# fftc register map
Vendor: Texas Instruments
Peripheral module from a debugger description file (folder Keystone2).
Registers are 32-bit, read-write, no defined reset value unless marked. A register's access mark holds for its fields unless they carry their own. Offsets are as the file gives them; lines under a group give offsets from that group; [hi:lo] are bit positions; {n}, {i} and the like mark numbered series; 'fields as' and 'values as' point back to an identical list; <NAME> marks a mode.

## FFTC_5
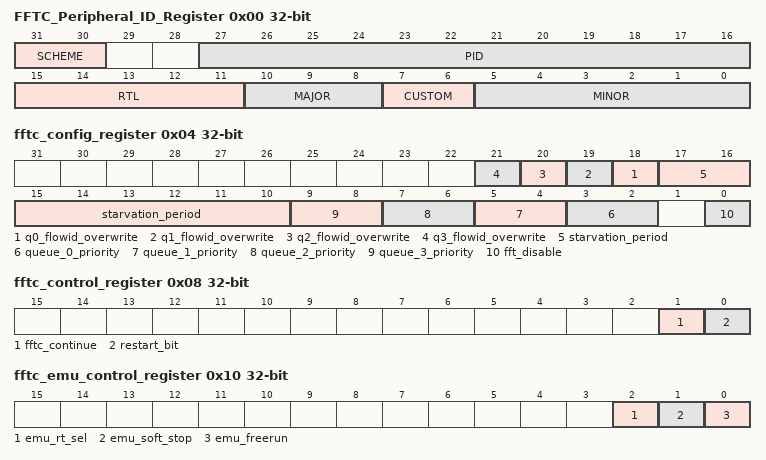
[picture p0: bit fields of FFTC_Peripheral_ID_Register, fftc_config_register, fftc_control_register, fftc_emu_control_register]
0x00 FFTC_Peripheral_ID_Register ro
  [31:30] SCHEME — PID Scheme
  [27:16] PID — Peripheral ID
  [15:11] RTL — RTL Rev Num
  [10:8] MAJOR — Major Rev Num
  [7:6] CUSTOM — Custom Rev Num
  [5:0] MINOR — Minor Rev Num
0x04 fftc_config_register
  [n+18] q{n}_flowid_overwrite (n=0..3) — Queue {n} flow_id overwrtie
  [17:10] starvation_period
  [2n+3:2n+2] queue_{n}_priority (n=0..3)
  [0] fft_disable — Discalbe FFT calculation
0x08 fftc_control_register wo
  [1] fftc_continue — FFTC resume work
  [0] restart_bit — FFTC SW restart
0x0C fftc_status_register ro
  [0] fftc_halted — FFTC has halted
0x10 fftc_emu_control_register
  [2] emu_rt_sel — FFTC emulation real time select
  [1] emu_soft_stop — FFTC emulation soft stop
  [0] emu_freerun — FFTC emulation free run
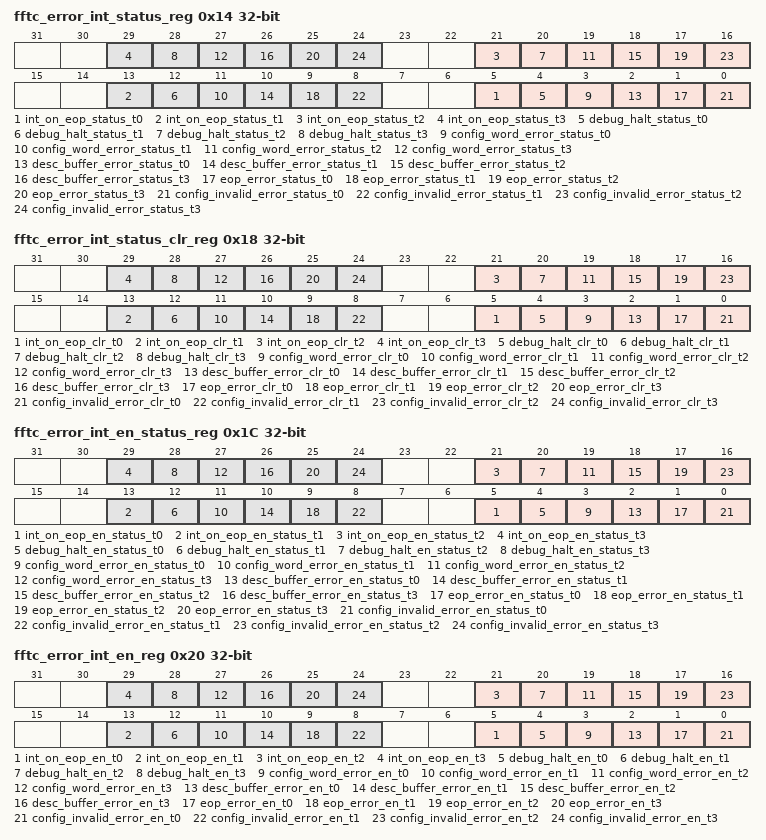
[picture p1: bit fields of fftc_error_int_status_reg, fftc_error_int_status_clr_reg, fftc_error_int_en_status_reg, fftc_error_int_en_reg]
0x14 fftc_error_int_status_reg
  [8n+5] int_on_eop_status_t{n} (n=0..3) — CPPI int on eop status and set
  [8n+4] debug_halt_status_t{n} (n=0..3) — debug halt interrupt status and set
  [8n+3] config_word_error_status_t{n} (n=0..3) — config word length error status and set
  [8n+2] desc_buffer_error_status_t{n} (n=0..3) — free descriptor buffer error status and set
  [8n+1] eop_error_status_t{n} (n=0..3) — eop error status and set
  [8n] config_invalid_error_status_t{n} (n=0..3) — config invalid error status and set
0x18 fftc_error_int_status_clr_reg wo
  [8n+5] int_on_eop_clr_t{n} (n=0..3) — CPPI int on eop status clear
  [8n+4] debug_halt_clr_t{n} (n=0..3) — debug halt interrupt status clear
  [8n+3] config_word_error_clr_t{n} (n=0..3) — config word length error statgus clear
  [8n+2] desc_buffer_error_clr_t{n} (n=0..3) — free descriptor buffer error status clear
  [8n+1] eop_error_clr_t{n} (n=0..3) — eop error status clear
  [8n] config_invalid_error_clr_t{n} (n=0..3) — config invalid error status clear
0x1C fftc_error_int_en_status_reg ro
  [8n+5] int_on_eop_en_status_t{n} (n=0..3) — CPPI int on eop status enabled
  [8n+4] debug_halt_en_status_t{n} (n=0..3) — debug halt interrupt status enabled
  [8n+3] config_word_error_en_status_t{n} (n=0..3) — config word length error statgus enabled
  [8n+2] desc_buffer_error_en_status_t{n} (n=0..3) — free descriptor buffer error status enabled
  [8n+1] eop_error_en_status_t{n} (n=0..3) — eop error status enabled
  [8n] config_invalid_error_en_status_t{n} (n=0..3) — config invalid error status enabled
0x20 fftc_error_int_en_reg
  [8n+5] int_on_eop_en_t{n} (n=0..3) — CPPI int on eop interrupt enable
  [8n+4] debug_halt_en_t{n} (n=0..3) — debug halt interrupt enable
  [8n+3] config_word_error_en_t{n} (n=0..3) — config word length error enable
  [8n+2] desc_buffer_error_en_t{n} (n=0..3) — free descriptor buffer error enable
  [8n+1] eop_error_en_t{n} (n=0..3) — eop error enable
  [8n] config_invalid_error_en_t{n} (n=0..3) — config invalid error enable
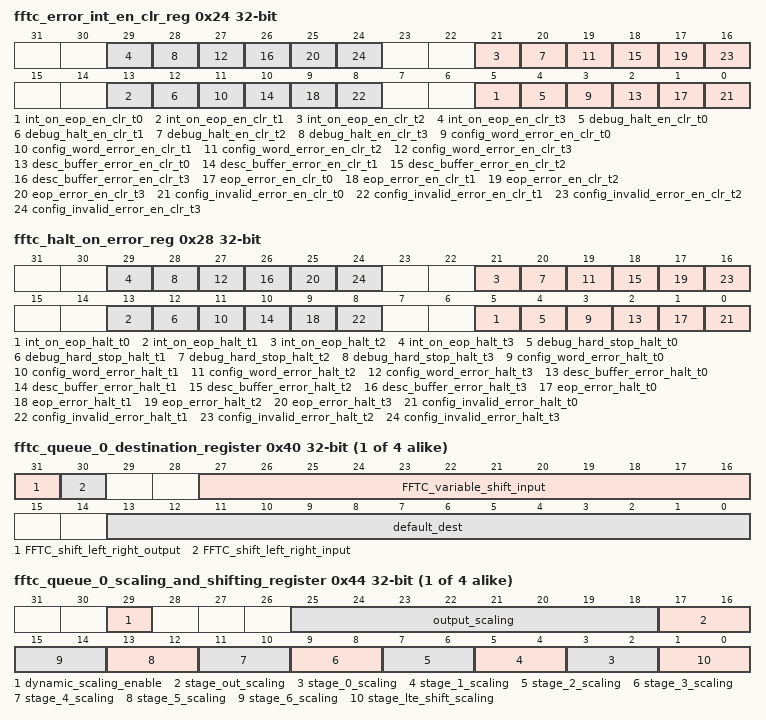
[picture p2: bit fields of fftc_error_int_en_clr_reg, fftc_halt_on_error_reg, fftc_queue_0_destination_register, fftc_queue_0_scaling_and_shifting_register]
0x24 fftc_error_int_en_clr_reg wo
  [8n+5] int_on_eop_en_clr_t{n} (n=0..3) — CPPI int on eop interrupt enable clear
  [8n+4] debug_halt_en_clr_t{n} (n=0..3) — debug halt interrupt enable clear
  [8n+3] config_word_error_en_clr_t{n} (n=0..3) — config word length error enable clear
  [8n+2] desc_buffer_error_en_clr_t{n} (n=0..3) — free descriptor buffer error enable clear
  [8n+1] eop_error_en_clr_t{n} (n=0..3) — eop error enable clear
  [8n] config_invalid_error_en_clr_t{n} (n=0..3) — config invalid error enable clear
0x28 fftc_halt_on_error_reg access per field
  [8n+5] int_on_eop_halt_t{n} rw (n=0..3) — CPPI int on eop interrupt halt on error
  [8n+4] debug_hard_stop_halt_t{n} ro (n=0..3) — CPPI hard stop halt on error status
  [8n+3] config_word_error_halt_t{n} rw (n=0..3) — config word length error halt
  [8n+2] desc_buffer_error_halt_t{n} rw (n=0..3) — free descriptor buffer error halt
  [8n+1] eop_error_halt_t{n} rw (n=0..3) — eop error halt
  [8n] config_invalid_error_halt_t{n} rw (n=0..3) — config invalid error halt
0x2C fftc_error_end_of_int_reg
  [7:0] eoi_val — EOI value
0x30 fftc_clipping_detect_register — (1 of 4, stride 4)
  [31:0] clipping_count — queue clipping count
{0x40+0x30*i} fftc_queue_{i}_destination_register (i=0..3)
  [31] FFTC_shift_left_right_output — set to 1 to enable
  [30] FFTC_shift_left_right_input — set to 1 to enable
  [27:16] FFTC_variable_shift_input — rotates the input sequence 2xFFTC_variable_shift_input samples to the right
  [13:0] default_dest — The CPPI queue to store the result. If set to 0x13ff for queue X use default value specified in the DMA channel
{0x44+0x30*i} fftc_queue_{i}_scaling_and_shifting_register (i=0..3)
  [29] dynamic_scaling_enable
  [25:18] output_scaling — output scaling factor
  [17:16] stage_out_scaling — output stage scale factor
  [2n+3:2n+2] stage_{n}_scaling (n=0..6) — stage {n} scale factor
  [1:0] stage_lte_shift_scaling — LTE shift scale factor
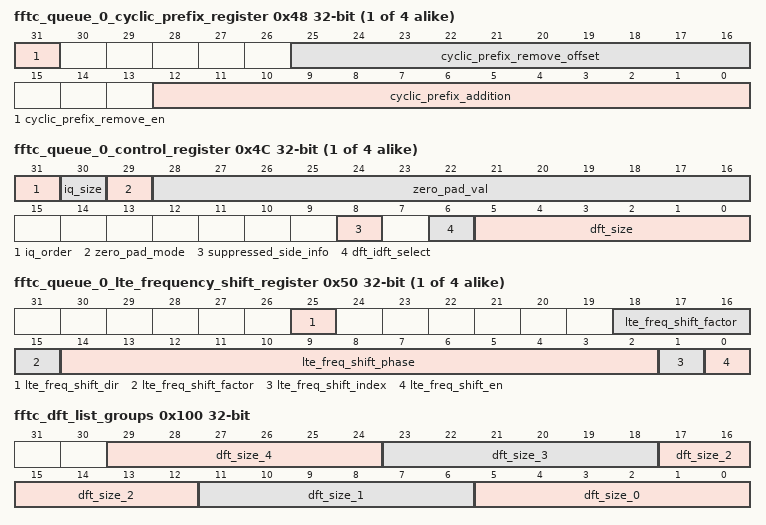
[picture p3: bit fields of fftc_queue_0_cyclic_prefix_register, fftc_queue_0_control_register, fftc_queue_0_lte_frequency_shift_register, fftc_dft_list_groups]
{0x48+0x30*i} fftc_queue_{i}_cyclic_prefix_register (i=0..3)
  [31] cyclic_prefix_remove_en — cyclic_pregix removal enable
  [25:16] cyclic_prefix_remove_offset — cyclic_pregix remove offset
  [12:0] cyclic_prefix_addition — cyclic_pregix addition length
{0x4C+0x30*i} fftc_queue_{i}_control_register (i=0..3)
  [31] iq_order — reverse iq order
  [30] iq_size — i or q size 8 bit
  [29] zero_pad_mode — zero pad enable
  [28:16] zero_pad_val — zero pad length
  [8] suppressed_side_info — suppress side info for CPPI Rx packets
  [6] dft_idft_select
  [5:0] dft_size
{0x50+0x30*i} fftc_queue_{i}_lte_frequency_shift_register (i=0..3)
  [25] lte_freq_shift_dir — LTE frequency shift direction
  [18:15] lte_freq_shift_factor — LTE frequency shift factor
  [14:2] lte_freq_shift_phase — LTE frequency shift phase
  [1] lte_freq_shift_index — LTE frequency shift index
  [0] lte_freq_shift_en — LTE frequency shift enable
0x100 fftc_dft_list_groups — (1 of 26, stride 4)
  [29:24] dft_size_4 — DFT size for fifth DFT in group no. 4
  [23:18] dft_size_3 — DFT size for fourth DFT in group no. 3
  [17:12] dft_size_2 — DFT size for third DFT in group no. 2
  [11:6] dft_size_1 — DFT size for second DFT in group no. 1
  [5:0] dft_size_0 — DFT size for first DFT in group no. 0
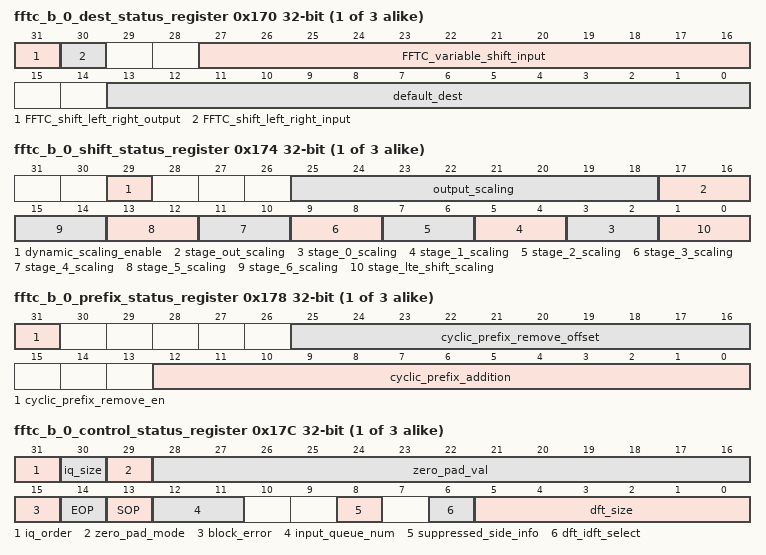
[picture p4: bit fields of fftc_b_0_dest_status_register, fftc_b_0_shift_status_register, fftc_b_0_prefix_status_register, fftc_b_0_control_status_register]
{0x170+0x20*i} fftc_b_{i}_dest_status_register ro (i=0..2)
  [31] FFTC_shift_left_right_output — set to 1 to enable
  [30] FFTC_shift_left_right_input — set to 1 to enable
  [27:16] FFTC_variable_shift_input — rotates the input sequence 2xFFTC_variable_shift_input samples to the right
  [13:0] default_dest — default destination queue for queue {i}
{0x174+0x20*i} fftc_b_{i}_shift_status_register ro (i=0..2)
  fields as fftc_queue_0_scaling_and_shifting_register
{0x178+0x20*i} fftc_b_{i}_prefix_status_register ro (i=0..2)
  fields as fftc_queue_0_cyclic_prefix_register
{0x17C+0x20*i} fftc_b_{i}_control_status_register ro (i=0..2)
  [31] iq_order — reverse iq order
  [30] iq_size — i or q size 8 bit
  [29] zero_pad_mode — zero pad enable
  [28:16] zero_pad_val — zero pad length
  [15] block_error
  [14] EOP
  [13] SOP
  [12:11] input_queue_num — queue number
  [8] suppressed_side_info — suppress side info for CPPI Rx packets
  [6] dft_idft_select
  [5:0] dft_size
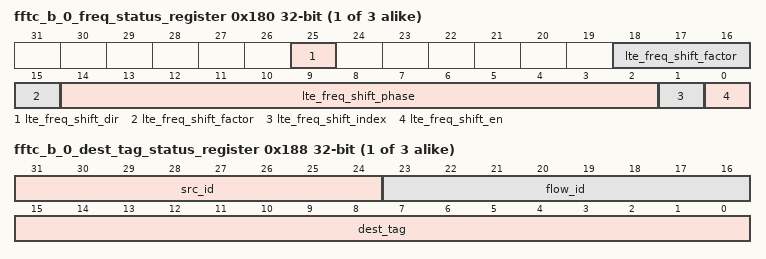
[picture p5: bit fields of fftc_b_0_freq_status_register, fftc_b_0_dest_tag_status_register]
{0x180+0x20*i} fftc_b_{i}_freq_status_register ro (i=0..2)
  fields as fftc_queue_0_lte_frequency_shift_register
{0x184+0x20*i} fftc_b_{i}_packet_size_status_register ro (i=0..2)
  [21:0] packet_size — block {i} packet size status
{0x188+0x20*i} fftc_b_{i}_dest_tag_status_register ro (i=0..2)
  [31:24] src_id
  [23:16] flow_id
  [15:0] dest_tag — block {i} destination tag status
